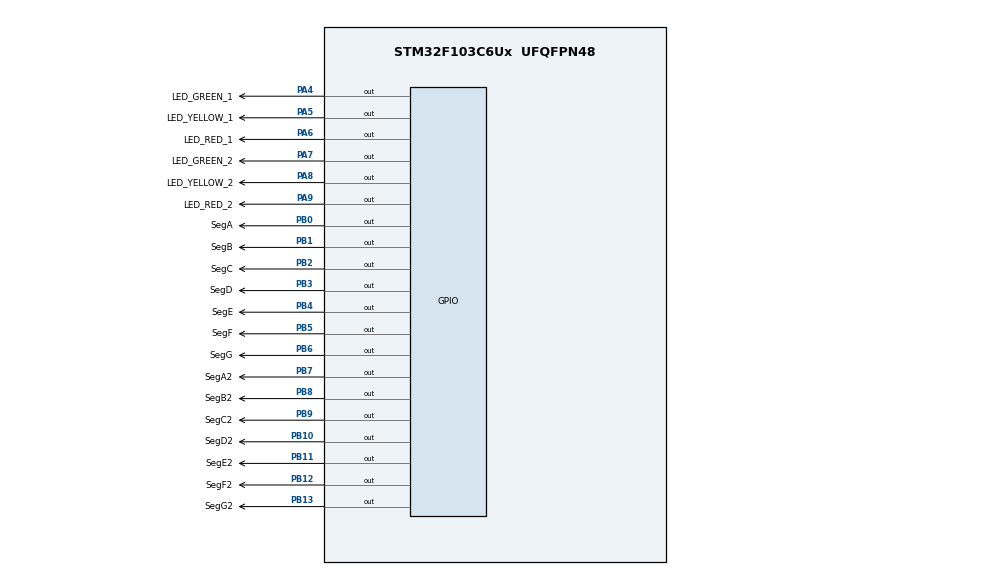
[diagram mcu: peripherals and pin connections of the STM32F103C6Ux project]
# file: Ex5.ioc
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Mcu.Family=STM32F1
Mcu.Name=STM32F103C6Ux
Mcu.Package=UFQFPN48
NVIC.PriorityGroup=NVIC_PRIORITYGROUP_4
PA4.GPIO_Label=LED_GREEN_1
PA4.Signal=GPIO_Output
PA5.GPIO_Label=LED_YELLOW_1
PA5.Signal=GPIO_Output
PA6.GPIO_Label=LED_RED_1
PA6.Signal=GPIO_Output
PA7.GPIO_Label=LED_GREEN_2
PA7.Signal=GPIO_Output
PA8.GPIO_Label=LED_YELLOW_2
PA8.Signal=GPIO_Output
PA9.GPIO_Label=LED_RED_2
PA9.Signal=GPIO_Output
PB0.GPIO_Label=SegA
PB0.Signal=GPIO_Output
PB1.GPIO_Label=SegB
PB1.Signal=GPIO_Output
PB10.GPIO_Label=SegD2
PB10.Signal=GPIO_Output
PB11.GPIO_Label=SegE2
PB11.Signal=GPIO_Output
PB12.GPIO_Label=SegF2
PB12.Signal=GPIO_Output
PB13.GPIO_Label=SegG2
PB13.Signal=GPIO_Output
PB2.GPIO_Label=SegC
PB2.Signal=GPIO_Output
PB3.GPIO_Label=SegD
PB3.Signal=GPIO_Output
PB4.GPIO_Label=SegE
PB4.Signal=GPIO_Output
PB5.GPIO_Label=SegF
PB5.Signal=GPIO_Output
PB6.GPIO_Label=SegG
PB6.Signal=GPIO_Output
PB7.GPIO_Label=SegA2
PB7.Signal=GPIO_Output
PB8.GPIO_Label=SegB2
PB8.Signal=GPIO_Output
PB9.GPIO_Label=SegC2
PB9.Signal=GPIO_Output
ProjectManager.HeapSize=0x200
ProjectManager.StackSize=0x400
ProjectManager.TargetToolchain=STM32CubeIDE
RCC.APB1Freq_Value=8000000
RCC.APB2Freq_Value=8000000
VP_SYS_VS_ND.Mode=No_Debug
board=custom

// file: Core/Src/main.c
/* USER CODE BEGIN Header */
/**
  ******************************************************************************
  * @file           : main.c
  * @brief          : Main program body
  ******************************************************************************
  * @attention
  *
  * <h2><center>&copy; Copyright (c) 2023 STMicroelectronics.
  * All rights reserved.</center></h2>
  *
  * This software component is licensed by ST under BSD 3-Clause license,
  * the "License"; You may not use this file except in compliance with the
  * License. You may obtain a copy of the License at:
  *                        opensource.org/licenses/BSD-3-Clause
  *
  ******************************************************************************
  */
/* USER CODE END Header */
#include "main.h"

/* USER CODE BEGIN Includes */
#include "myLib.h"
/* USER CODE END Includes */

void SystemClock_Config(void);
static void MX_GPIO_Init(void);

int main(void)
{

  /* MCU Configuration--------------------------------------------------------*/

  /* Reset of all peripherals, Initializes the Flash interface and the Systick. */
  HAL_Init();

  /* Configure the system clock */
  SystemClock_Config();

  /* Initialize all configured peripherals */
  MX_GPIO_Init();
  /* USER CODE BEGIN 2 */
  int8_t counter1 = -1;
  int8_t counter2 = -1;
  int8_t trafficState = 0; //0:Green-Yellow,1:Yellow-Red, 2:Red-Green, 3:Red-Green for light 1
  	  	  	  	  	  	  	//	Red-Green      Red-Green     Green-Yellow Yellow-Red for light2
  /* USER CODE END 2 */
  /* Infinite loop */
  while (1)
  {
	  if (counter1 < 0 || counter2 < 0) {
		  if (trafficState == 0) {
			  counter1 = 2;
			  counter2 = 4;
			  HAL_GPIO_WritePin(LED_GREEN_1_GPIO_Port, LED_GREEN_1_Pin, RESET);
			  HAL_GPIO_WritePin(LED_YELLOW_1_GPIO_Port, LED_YELLOW_1_Pin, SET);
			  HAL_GPIO_WritePin(LED_RED_1_GPIO_Port, LED_RED_1_Pin, SET);

			  HAL_GPIO_WritePin(LED_GREEN_2_GPIO_Port, LED_GREEN_2_Pin, SET);
			  HAL_GPIO_WritePin(LED_YELLOW_2_GPIO_Port, LED_YELLOW_2_Pin, SET);
			  HAL_GPIO_WritePin(LED_RED_2_GPIO_Port, LED_RED_2_Pin, RESET);
		  }
		  else if (trafficState == 1) {
			  counter1 = 1;
			  HAL_GPIO_WritePin(LED_GREEN_1_GPIO_Port, LED_GREEN_1_Pin, SET);
			  HAL_GPIO_WritePin(LED_YELLOW_1_GPIO_Port, LED_YELLOW_1_Pin, RESET);
			  HAL_GPIO_WritePin(LED_RED_1_GPIO_Port, LED_RED_1_Pin, SET);

			  HAL_GPIO_WritePin(LED_GREEN_2_GPIO_Port, LED_GREEN_2_Pin, SET);
			  HAL_GPIO_WritePin(LED_YELLOW_2_GPIO_Port, LED_YELLOW_2_Pin, SET);
			  HAL_GPIO_WritePin(LED_RED_2_GPIO_Port, LED_RED_2_Pin, RESET);
		  }
		  else if (trafficState == 2) {
			  counter1 = 4;
			  counter2 = 2;
			  HAL_GPIO_WritePin(LED_GREEN_1_GPIO_Port, LED_GREEN_1_Pin, SET);
			  HAL_GPIO_WritePin(LED_YELLOW_1_GPIO_Port, LED_YELLOW_1_Pin, SET);
			  HAL_GPIO_WritePin(LED_RED_1_GPIO_Port, LED_RED_1_Pin, RESET);

			  HAL_GPIO_WritePin(LED_GREEN_2_GPIO_Port, LED_GREEN_2_Pin, RESET);
			  HAL_GPIO_WritePin(LED_YELLOW_2_GPIO_Port, LED_YELLOW_2_Pin, SET);
			  HAL_GPIO_WritePin(LED_RED_2_GPIO_Port, LED_RED_2_Pin, SET);
		  }
		  else {
			  trafficState = -1;
			  counter2 = 1;
			  HAL_GPIO_WritePin(LED_GREEN_1_GPIO_Port, LED_GREEN_1_Pin, SET);
			  HAL_GPIO_WritePin(LED_YELLOW_1_GPIO_Port, LED_YELLOW_1_Pin, SET);
			  HAL_GPIO_WritePin(LED_RED_1_GPIO_Port, LED_RED_1_Pin, RESET);

			  HAL_GPIO_WritePin(LED_GREEN_2_GPIO_Port, LED_GREEN_2_Pin, SET);
			  HAL_GPIO_WritePin(LED_YELLOW_2_GPIO_Port, LED_YELLOW_2_Pin, RESET);
			  HAL_GPIO_WritePin(LED_RED_2_GPIO_Port, LED_RED_2_Pin, SET);
		  }
		  trafficState++;
	  }
	  display7SEG1(counter1);
	  display7SEG2(counter2);
      counter1--;
	  counter2--;
	  HAL_Delay(1000);
  }
}

void SystemClock_Config(void)
{
  RCC_OscInitTypeDef RCC_OscInitStruct = {0};
  RCC_ClkInitTypeDef RCC_ClkInitStruct = {0};

  /** Initializes the RCC Oscillators according to the specified parameters
  * in the RCC_OscInitTypeDef structure.
  */
  RCC_OscInitStruct.OscillatorType = RCC_OSCILLATORTYPE_HSI;
  RCC_OscInitStruct.HSIState = RCC_HSI_ON;
  RCC_OscInitStruct.HSICalibrationValue = RCC_HSICALIBRATION_DEFAULT;
  RCC_OscInitStruct.PLL.PLLState = RCC_PLL_NONE;
  if (HAL_RCC_OscConfig(&RCC_OscInitStruct) != HAL_OK)
  {
    Error_Handler();
  }
  /** Initializes the CPU, AHB and APB buses clocks
  */
  RCC_ClkInitStruct.ClockType = RCC_CLOCKTYPE_HCLK|RCC_CLOCKTYPE_SYSCLK
                              |RCC_CLOCKTYPE_PCLK1|RCC_CLOCKTYPE_PCLK2;
  RCC_ClkInitStruct.SYSCLKSource = RCC_SYSCLKSOURCE_HSI;
  RCC_ClkInitStruct.AHBCLKDivider = RCC_SYSCLK_DIV1;
  RCC_ClkInitStruct.APB1CLKDivider = RCC_HCLK_DIV1;
  RCC_ClkInitStruct.APB2CLKDivider = RCC_HCLK_DIV1;

  if (HAL_RCC_ClockConfig(&RCC_ClkInitStruct, FLASH_LATENCY_0) != HAL_OK)
  {
    Error_Handler();
  }
}

static void MX_GPIO_Init(void)
{
  GPIO_InitTypeDef GPIO_InitStruct = {0};

  /* GPIO Ports Clock Enable */
  __HAL_RCC_GPIOA_CLK_ENABLE();
  __HAL_RCC_GPIOB_CLK_ENABLE();

  /*Configure GPIO pin Output Level */
  HAL_GPIO_WritePin(GPIOA, LED_GREEN_1_Pin|LED_YELLOW_1_Pin|LED_RED_1_Pin|LED_GREEN_2_Pin
                          |LED_YELLOW_2_Pin|LED_RED_2_Pin, GPIO_PIN_RESET);

  /*Configure GPIO pin Output Level */
  HAL_GPIO_WritePin(GPIOB, SegA_Pin|SegB_Pin|SegC_Pin|SegD2_Pin
                          |SegE2_Pin|SegF2_Pin|SegG2_Pin|SegD_Pin
                          |SegE_Pin|SegF_Pin|SegG_Pin|SegA2_Pin
                          |SegB2_Pin|SegC2_Pin, GPIO_PIN_RESET);

  /*Configure GPIO pins : LED_GREEN_1_Pin LED_YELLOW_1_Pin LED_RED_1_Pin LED_GREEN_2_Pin
                           LED_YELLOW_2_Pin LED_RED_2_Pin */
  GPIO_InitStruct.Pin = LED_GREEN_1_Pin|LED_YELLOW_1_Pin|LED_RED_1_Pin|LED_GREEN_2_Pin
                          |LED_YELLOW_2_Pin|LED_RED_2_Pin;
  GPIO_InitStruct.Mode = GPIO_MODE_OUTPUT_PP;
  GPIO_InitStruct.Pull = GPIO_NOPULL;
  GPIO_InitStruct.Speed = GPIO_SPEED_FREQ_LOW;
  HAL_GPIO_Init(GPIOA, &GPIO_InitStruct);

  /*Configure GPIO pins : SegA_Pin SegB_Pin SegC_Pin SegD2_Pin
                           SegE2_Pin SegF2_Pin SegG2_Pin SegD_Pin
                           SegE_Pin SegF_Pin SegG_Pin SegA2_Pin
                           SegB2_Pin SegC2_Pin */
  GPIO_InitStruct.Pin = SegA_Pin|SegB_Pin|SegC_Pin|SegD2_Pin
                          |SegE2_Pin|SegF2_Pin|SegG2_Pin|SegD_Pin
                          |SegE_Pin|SegF_Pin|SegG_Pin|SegA2_Pin
                          |SegB2_Pin|SegC2_Pin;
  GPIO_InitStruct.Mode = GPIO_MODE_OUTPUT_PP;
  GPIO_InitStruct.Pull = GPIO_NOPULL;
  GPIO_InitStruct.Speed = GPIO_SPEED_FREQ_LOW;
  HAL_GPIO_Init(GPIOB, &GPIO_InitStruct);

}

void Error_Handler(void)
{
  __disable_irq();
  while (1)
  {
  }
}

/************************ (C) COPYRIGHT STMicroelectronics *****END OF FILE****/
